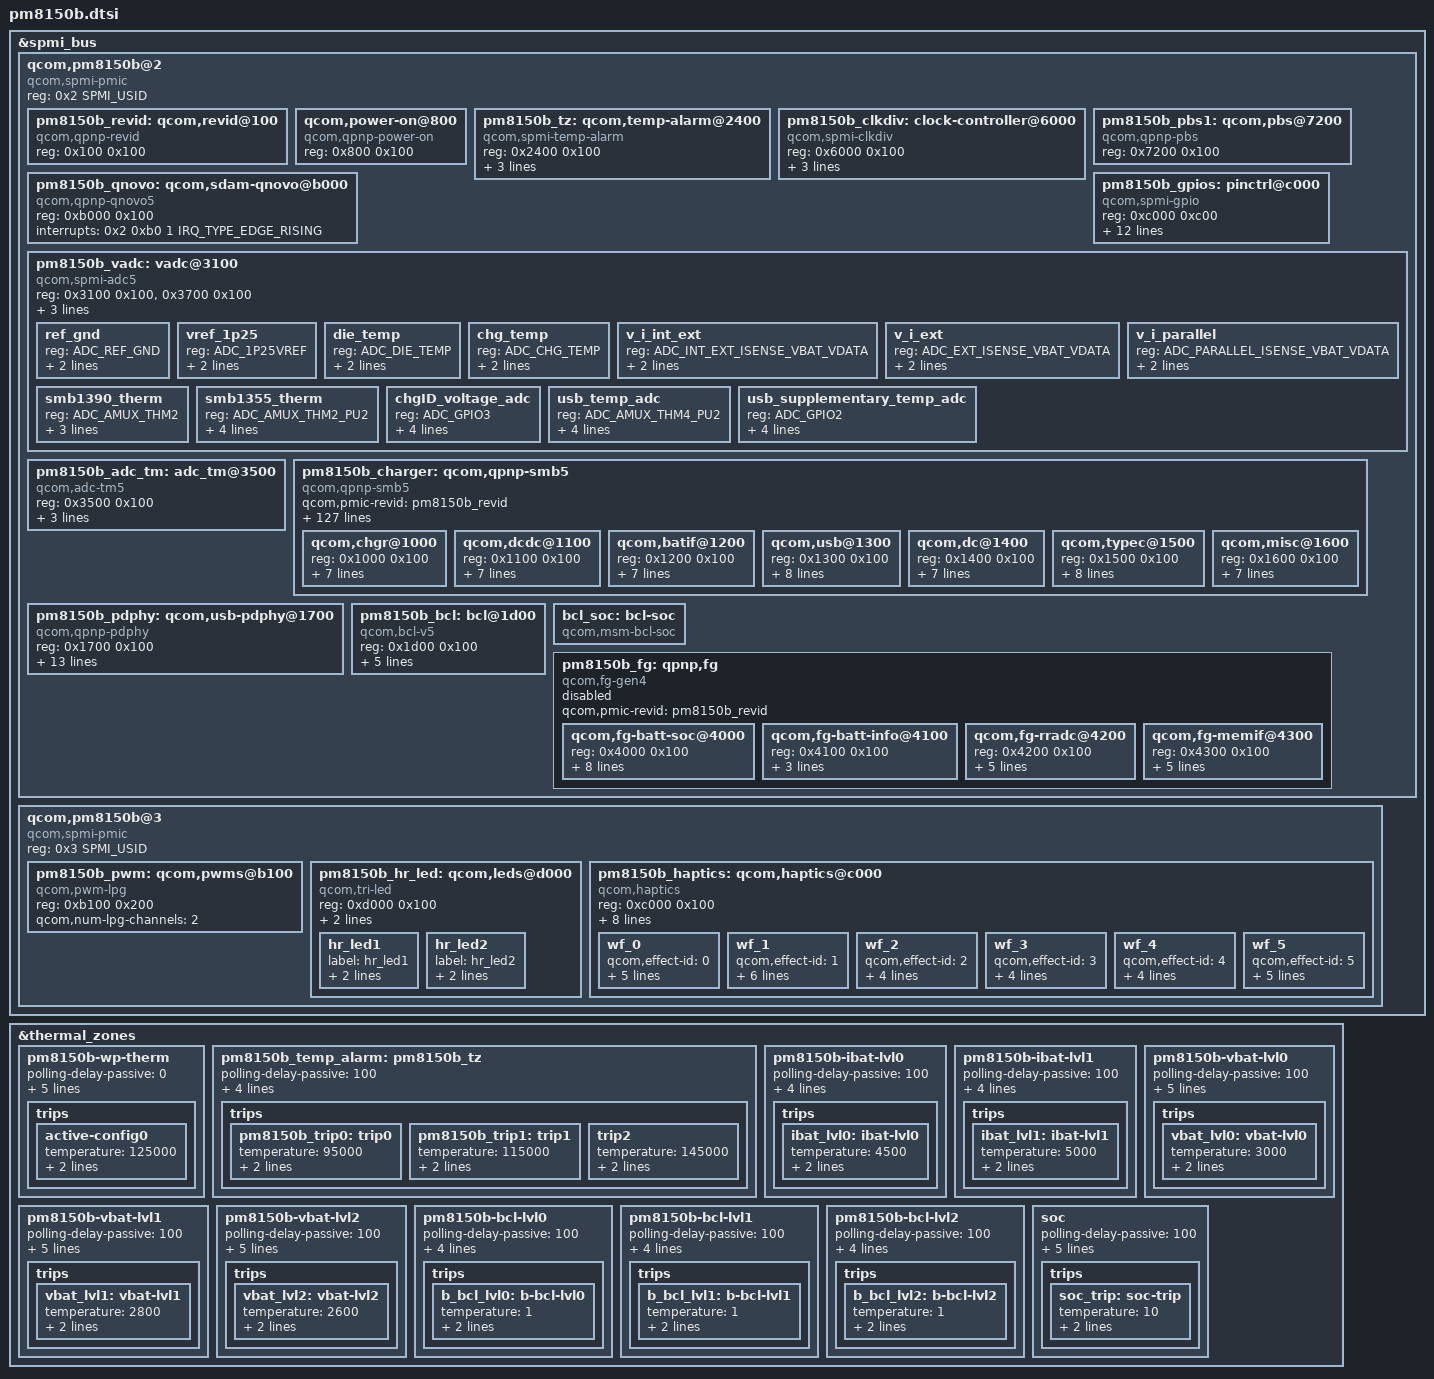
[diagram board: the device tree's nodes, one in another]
/*
 * Copyright (c) 2017-2019, The Linux Foundation. All rights reserved.
 *
 * This program is free software; you can redistribute it and/or modify
 * it under the terms of the GNU General Public License version 2 and
 * only version 2 as published by the Free Software Foundation.
 *
 * This program is distributed in the hope that it will be useful,
 * but WITHOUT ANY WARRANTY; without even the implied warranty of
 * MERCHANTABILITY or FITNESS FOR A PARTICULAR PURPOSE.  See the
 * GNU General Public License for more details.
 */

#include <dt-bindings/spmi/spmi.h>
#include <dt-bindings/interrupt-controller/irq.h>
#include <dt-bindings/iio/qcom,spmi-vadc.h>

&spmi_bus {
	#address-cells = <2>;
	#size-cells = <0>;

	qcom,pm8150b@2 {
		compatible = "qcom,spmi-pmic";
		reg = <0x2 SPMI_USID>;
		#address-cells = <2>;
		#size-cells = <0>;

		pm8150b_revid: qcom,revid@100 {
			compatible = "qcom,qpnp-revid";
			reg = <0x100 0x100>;
		};

		qcom,power-on@800 {
			compatible = "qcom,qpnp-power-on";
			reg = <0x800 0x100>;
		};

		pm8150b_tz: qcom,temp-alarm@2400 {
			compatible = "qcom,spmi-temp-alarm";
			reg = <0x2400 0x100>;
			interrupts = <0x2 0x24 0x0 IRQ_TYPE_EDGE_RISING>;
			io-channels = <&pm8150b_vadc ADC_DIE_TEMP>;
			io-channel-names = "thermal";
			#thermal-sensor-cells = <0>;
			qcom,temperature-threshold-set = <1>;
		};

		pm8150b_clkdiv: clock-controller@6000 {
			compatible = "qcom,spmi-clkdiv";
			reg = <0x6000 0x100>;
			#clock-cells = <1>;
			qcom,num-clkdivs = <1>;
			clock-output-names = "pm8150b_div_clk1";
			clocks = <&clock_rpmh RPMH_CXO_CLK>;
			clock-names = "xo";
		};

		pm8150b_pbs1: qcom,pbs@7200 {
			compatible = "qcom,qpnp-pbs";
			reg = <0x7200 0x100>;
		};

		pm8150b_qnovo: qcom,sdam-qnovo@b000 {
			compatible = "qcom,qpnp-qnovo5";
			reg = <0xb000 0x100>;
			interrupts = <0x2 0xb0 1 IRQ_TYPE_EDGE_RISING>;
			interrupt-names = "ptrain-done";
		};

		pm8150b_gpios: pinctrl@c000 {
			compatible = "qcom,spmi-gpio";
			reg = <0xc000 0xc00>;
			interrupts = <0x2 0xc0 0 IRQ_TYPE_NONE>,
					<0x2 0xc1 0 IRQ_TYPE_NONE>,
					<0x2 0xc4 0 IRQ_TYPE_NONE>,
					<0x2 0xc5 0 IRQ_TYPE_NONE>,
					//#ifdef VENDOR_EDIT
					<0x2 0xc6 0 IRQ_TYPE_NONE>,
					//#endif
					<0x2 0xc7 0 IRQ_TYPE_NONE>,
					<0x2 0xc8 0 IRQ_TYPE_NONE>,
					<0x2 0xc9 0 IRQ_TYPE_NONE>,
					<0x2 0xca 0 IRQ_TYPE_NONE>,
					<0x2 0xcb 0 IRQ_TYPE_NONE>;
			interrupt-names = "pm8150b_gpio1", "pm8150b_gpio2",
					"pm8150b_gpio5", "pm8150b_gpio6",
					//#ifdef VENDOR_EDIT
					"pm8150b_gpio7",
					//#endif
					"pm8150b_gpio8", "pm8150b_gpio9",
					"pm8150b_gpio10", "pm8150b_gpio11",
					"pm8150b_gpio12";
			gpio-controller;
			#gpio-cells = <2>;
			//#ifdef VENDOR_EDIT
			qcom,gpios-disallowed = <3 4>;
			//#else
			//qcom,gpios-disallowed = <3 4 7>;
			//#endif
		};

		pm8150b_vadc: vadc@3100 {
			compatible = "qcom,spmi-adc5";
			reg = <0x3100 0x100>, <0x3700 0x100>;
			reg-names = "adc5-usr-base", "adc5-cal-base";
			#address-cells = <1>;
			#size-cells = <0>;
			interrupts = <0x2 0x31 0x0 IRQ_TYPE_EDGE_RISING>;
			interrupt-names = "eoc-int-en-set";
			qcom,adc-vdd-reference = <1875>;
			#io-channel-cells = <1>;
			io-channel-ranges;

			/* Channel node */
			ref_gnd {
				reg = <ADC_REF_GND>;
				label = "ref_gnd";
				qcom,pre-scaling = <1 1>;
			};

			vref_1p25 {
				reg = <ADC_1P25VREF>;
				label = "vref_1p25";
				qcom,pre-scaling = <1 1>;
			};

			die_temp {
				reg = <ADC_DIE_TEMP>;
				label = "die_temp";
				qcom,pre-scaling = <1 1>;
			};

			chg_temp {
				reg = <ADC_CHG_TEMP>;
				label = "chg_temp";
				qcom,pre-scaling = <1 1>;
			};

			v_i_int_ext {
				reg = <ADC_INT_EXT_ISENSE_VBAT_VDATA>;
				label = "v_i_int_vbat_vdata";
				qcom,pre-scaling = <1 1>;
			};

			v_i_ext {
				reg = <ADC_EXT_ISENSE_VBAT_VDATA>;
				label = "v_i_int_ext_vbat_vdata";
				qcom,pre-scaling = <1 1>;
			};

			v_i_parallel {
				reg = <ADC_PARALLEL_ISENSE_VBAT_VDATA>;
				label = "v_i_parallel_vbat_vdata";
				qcom,pre-scaling = <1 1>;
			};

			smb1390_therm {
				reg = <ADC_AMUX_THM2>;
				label = "smb1390_therm";
				qcom,hw-settle-time = <200>;
				qcom,pre-scaling = <1 1>;
			};

			smb1355_therm {
				reg = <ADC_AMUX_THM2_PU2>;
				label = "smb1355_therm";
				qcom,ratiometric;
				qcom,hw-settle-time = <200>;
				qcom,pre-scaling = <1 1>;
			};
			chgID_voltage_adc {
				reg = <ADC_GPIO3>;
				label = "chgID_voltage_adc";
				qcom,pre-scaling = <1 1>;
				qcom,ratiometric;
				qcom,hw-settle-time = <200>;
			};
			usb_temp_adc {
				reg = <ADC_AMUX_THM4_PU2>;
				label = "usb_temp_adc";
				qcom,pre-scaling = <1 1>;
				qcom,ratiometric;
				qcom,hw-settle-time = <200>;
			};
			usb_supplementary_temp_adc {
				reg = <ADC_GPIO2>;
				label = "usb_supplementary_temp_adc";
				qcom,pre-scaling = <1 1>;
				qcom,ratiometric;
				qcom,hw-settle-time = <200>;
			};
			// #endif
		};

		pm8150b_adc_tm: adc_tm@3500 {
			compatible = "qcom,adc-tm5";
			reg = <0x3500 0x100>;
			interrupts = <0x2 0x35 0x0 IRQ_TYPE_EDGE_RISING>;
			interrupt-names = "thr-int-en";
			#address-cells = <1>;
			#size-cells = <0>;
			#thermal-sensor-cells = <1>;
			io-channels = <&pm8150b_vadc ADC_AMUX_THM1_PU2>;
			qcom,pmic-revid = <&pm8150b_revid>;
		};

		pm8150b_charger: qcom,qpnp-smb5 {
			compatible = "qcom,qpnp-smb5";
			#address-cells = <1>;
			#size-cells = <1>;
			#cooling-cells = <2>;

			qcom,pmic-revid = <&pm8150b_revid>;

			qcom,thermal-mitigation
					= <3000000 1500000 1000000 500000>;

			qcom,charger-temp-max = <800>;
			qcom,smb-temp-max = <800>;
			//for smb5:
			qcom,usb-icl-ua = <2000000>;
			qcom,fcc-max-ua = <2000000>;
			//qcom,fv-max-uv = <4373000>;
			qcom,hvdcp-disable;
			//io-channels = <&pm8150b_vadc ADC_GPIO3>;
			//io-channel-names = "chgID_voltage_adc";
			//qcom,otg-cl-ua = <2000000>;
			qcom,float-option = <1>;
			qcom,oplus-pps-usbpd-detection = <&pm8150b_pdphy>;

			//for oplus chg framework:
			qcom,input_current_charger_ma = <2000>;
			qcom,input_current_usb_ma = <500>;
			qcom,input_current_cdp_ma = <1500>;
			qcom,input_current_led_ma = <1200>;
			qcom,input_current_led_ma_high = <1200>;
			qcom,input_current_led_ma_warm = <1500>;
			qcom,input_current_led_ma_normal = <2000>;

			qcom,input_current_camera_ma = <1200>;
			//qcom,input_current_led_ma_overtemp = <900>;
			qcom,overtemp_bat_decidegc = <350>;
			qcom,iterm_disabled = <0>;
			qcom,iterm_ma = <215>;
			qcom,recharge-mv = <100>;
			qcom,batt_capacity_mah = <4065>;/*typical capacity*/
			//qcom,batt_capacity_mah = <3950>; /*rated capacity*/

			qcom,removed_bat_decidegc = <190>;  /*<-19C*/

			qcom,cold_bat_decidegc = <20>;  /*-2C~0C*/
			qcom,temp_cold_vfloat_mv = <3980>;
			qcom,temp_cold_fastchg_current_ma = <314>;

			qcom,little_cold_bat_decidegc = <0>;	/*0C~5C*/
			qcom,temp_little_cold_vfloat_mv = <4435>;
			qcom,temp_little_cold_fastchg_current_ma_high = <1850>;
			qcom,temp_little_cold_fastchg_current_ma_low = <1100>;
			qcom,temp_little_cold_fastchg_current_ma = <1076>;

			qcom,cool_bat_decidegc = <50>;	/*5C~12C*/
			qcom,temp_cool_vfloat_mv = <4435>;
			qcom,temp_cool_fastchg_current_ma_high = <2100>;
			qcom,temp_cool_fastchg_current_ma_low = <1850>;

			qcom,little_cool_bat_decidegc = <120>;	/*12C~16C*/
			qcom,temp_little_cool_vfloat_mv = <4435>;
			qcom,temp_little_cool_fastchg_current_ma = <2100>;

			qcom,normal_bat_decidegc = <160>;	/*16C~45C*/
			qcom,temp_normal_fastchg_current_ma = <2100>;
			qcom,temp_normal_vfloat_mv = <4435>;

			qcom,warm_bat_decidegc = <450>;		/*45C~53C*/ /*8pin Bat Vooc project need add 3 degree C*/
			qcom,temp_warm_vfloat_mv = <4130>;
			qcom,temp_warm_fastchg_current_ma = <1100>;

			qcom,hot_bat_decidegc = <530>;

			qcom,non_standard_vfloat_mv = <3980>;
			qcom,non_standard_fastchg_current_ma = <512>;

			qcom,short_c_bat_cv_mv = <4330>;
			qcom,short_c_bat_vfloat_mv = <3800>;
			qcom,short_c_bat_fastchg_current_ma = <512>;

			qcom,cold_vfloat_sw_limit = <3930>;
			qcom,little_cold_vfloat_sw_limit = <4385>;
			qcom,cool_vfloat_sw_limit = <4385>;
			qcom,little_cool_vfloat_sw_limit = <4385>;
			qcom,normal_vfloat_sw_limit = <4385>;
			qcom,warm_vfloat_sw_limit = <4080>;
			qcom,non_standard_vfloat_sw_limit = <3930>;
			qcom,short_c_bat_vfloat_sw_limit = <3750>;

			qcom,max_chg_time_sec = <36000>;
			qcom,charger_hv_thr = <5700>;
			qcom,charger_recv_thr = <5500>;
			qcom,charger_lv_thr = <3400>;
			qcom,vbatt_full_thr = <4400>;
			qcom,vbatt_hv_thr = <4500>;
			qcom,vfloat_step_mv = <8>;
			qcom,non_standard_vfloat_over_sw_limit = <3990>;
			qcom,cold_vfloat_over_sw_limit = <3990>;
			qcom,little_cold_vfloat_over_sw_limit = <4445>;
			qcom,cool_vfloat_over_sw_limit = <4445>;
			qcom,little_cool_vfloat_over_sw_limit = <4445>;
			qcom,normal_vfloat_over_sw_limit = <4445>;
			qcom,warm_vfloat_over_sw_limit = <4140>;

			qcom,vbatt_power_off = <3300>;
			qcom,vbatt_soc_1 = <3410>;
			qcom,vooc_project = <1>;
			qcom,vbatt_num = <1>;
			qcom,ffc_support;

			qcom,normal_vterm_hw_inc = <18>;
			qcom,non_normal_vterm_hw_inc = <18>;

			qcom,ff1_normal_fastchg_ma = <1060>;
			qcom,ffc2_normal_fastchg_ma = <820>;/*12C~35c*/
			qcom,ffc2_temp_warm_decidegc = <350>;
			qcom,ffc2_warm_fastchg_ma = <870>;/*35C~40c*/
			qcom,ffc2_temp_high_decidegc = <400>;
			qcom,ffc2_temp_low_decidegc = <120>;
			qcom,ffc2_exit_step_ma = <170>;

			qcom,ffc_normal_vfloat_sw_limit = <4480>;
			qcom,ffc_temp_normal_vfloat_mv = <4550>;
			qcom,ffc_normal_vfloat_over_sw_limit = <4550>;

			qcom,default_iterm_ma = <215>;
			qcom,default_temp_normal_fastchg_current_ma = <2000>;
			qcom,default_normal_vfloat_sw_limit = <4385>;
			qcom,default_temp_normal_vfloat_mv = <4435>;
			qcom,default_normal_vfloat_over_sw_limit = <4445>;

			qcom,default_temp_little_cool_fastchg_current_ma = <2000>;
			qcom,default_little_cool_vfloat_sw_limit = <4385>;
			qcom,default_temp_little_cool_vfloat_mv = <4435>;
			qcom,default_little_cool_vfloat_over_sw_limit = <4445>;

			//qcom,offset_temp = <30>;
			//for control:
			//qcom,suspend_after_full;
			qcom,check_batt_full_by_sw;
			qcom,external_gauge;
			qcom,chg_ctrl_by_lcd;
			qcom,chg_ctrl_by_camera;
			qcom,sw_vfloat_over_protect_enable;

			qcom,chargerid_switch-gpio = <&tlmm 94 0x00>;
			qcom,ship-gpio = <&tlmm 21 0x00>;
			qcom,ccdetect-gpio = <&tlmm 91 0x00>;
			//qcom,shortc-gpio = <&tlmm 43 0x00>;
			qcom,dischg-gpio = <&pm8150_gpios 9 0x00>;
			qcom,shipmode-id-gpio = <&tlmm 25 0x00>;

			pinctrl-names = "default",
					"chargerid_switch_active", "chargerid_switch_sleep", "chargerid_switch_default",
					"ship_active", "ship_sleep",
					"ccdetect_active", "ccdetect_sleep",
					"dischg_enable", "dischg_disable",
					"chg_qupv3_se12_2uart_default", "chg_qupv3_se12_2uart_sleep",
					"gpio1_adc_default",
					"shipmode_id_active";

			pinctrl-0 = <&gpio7_adc_default>;
			pinctrl-1 = <&chargerid_switch_active>;
			pinctrl-2 = <&chargerid_switch_sleep>;
			pinctrl-3 = <&chargerid_switch_default>;
			pinctrl-4 = <&ship_active>;
			pinctrl-5 = <&ship_sleep>;
			pinctrl-6 = <&ccdetect_active>;
			pinctrl-7 = <&ccdetect_sleep>;
			pinctrl-8 = <&dischg_enable>;
			pinctrl-9 = <&dischg_disable>;
			pinctrl-10 = <&chg_qupv3_se12_2uart_default>;
			pinctrl-11 = <&chg_qupv3_se12_2uart_sleep>;
			pinctrl-12 = <&gpio1_adc_default>;
			pinctrl-13 = <&shipmode_id_active>;
			//#endif //VENDOR_EDIT
			qcom,chgr@1000 {
				reg = <0x1000 0x100>;
				interrupts =
					<0x2 0x10 0x0 IRQ_TYPE_EDGE_RISING>,
					<0x2 0x10 0x1 IRQ_TYPE_EDGE_RISING>,
					<0x2 0x10 0x2 IRQ_TYPE_EDGE_RISING>,
					<0x2 0x10 0x3 IRQ_TYPE_EDGE_RISING>,
					<0x2 0x10 0x4 IRQ_TYPE_EDGE_RISING>,
					<0x2 0x10 0x6 IRQ_TYPE_EDGE_BOTH>,
					<0x2 0x10 0x7 IRQ_TYPE_EDGE_BOTH>;

				interrupt-names = "chgr-error",
						  "chg-state-change",
						  "step-chg-state-change",
						  "step-chg-soc-update-fail",
						  "step-chg-soc-update-req",
						  "vph-alarm",
						  "vph-drop-prechg";
			};

			qcom,dcdc@1100 {
				reg = <0x1100 0x100>;
				interrupts =
					<0x2 0x11 0x0 IRQ_TYPE_EDGE_BOTH>,
					<0x2 0x11 0x1 IRQ_TYPE_EDGE_BOTH>,
					<0x2 0x11 0x2 IRQ_TYPE_EDGE_BOTH>,
					<0x2 0x11 0x4 IRQ_TYPE_EDGE_BOTH>,
					<0x2 0x11 0x5 IRQ_TYPE_EDGE_BOTH>,
					<0x2 0x11 0x6 IRQ_TYPE_EDGE_BOTH>,
					<0x2 0x11 0x7 IRQ_TYPE_EDGE_BOTH>;

				interrupt-names = "otg-fail",
						  "otg-oc-disable-sw",
						  "otg-oc-hiccup",
						  "high-duty-cycle",
						  "input-current-limiting",
						  "concurrent-mode-disable",
						  "switcher-power-ok";
			};

			qcom,batif@1200 {
				reg = <0x1200 0x100>;
				interrupts =
					<0x2 0x12 0x0 IRQ_TYPE_EDGE_RISING>,
					<0x2 0x12 0x2 IRQ_TYPE_EDGE_BOTH>,
					<0x2 0x12 0x3 IRQ_TYPE_EDGE_BOTH>,
					<0x2 0x12 0x4 IRQ_TYPE_EDGE_BOTH>,
					<0x2 0x12 0x5 IRQ_TYPE_EDGE_BOTH>,
					<0x2 0x12 0x6 IRQ_TYPE_EDGE_BOTH>,
					<0x2 0x12 0x7 IRQ_TYPE_EDGE_BOTH>;

				interrupt-names = "bat-temp",
						  "bat-ov",
						  "bat-low",
						  "bat-therm-or-id-missing",
						  "bat-terminal-missing",
						  "buck-oc",
						  "vph-ov";
			};

			qcom,usb@1300 {
				reg = <0x1300 0x100>;
				interrupts =
					<0x2 0x13 0x0 IRQ_TYPE_EDGE_BOTH>,
					<0x2 0x13 0x1 IRQ_TYPE_EDGE_BOTH>,
					<0x2 0x13 0x2 IRQ_TYPE_EDGE_BOTH>,
					<0x2 0x13 0x3 IRQ_TYPE_EDGE_BOTH>,
					<0x2 0x13 0x4 IRQ_TYPE_EDGE_BOTH>,
					<0x2 0x13 0x5 IRQ_TYPE_EDGE_BOTH>,
					<0x2 0x13 0x6 IRQ_TYPE_EDGE_RISING>,
					<0x2 0x13 0x7 IRQ_TYPE_EDGE_RISING>;

				interrupt-names = "usbin-collapse",
						  "usbin-vashdn",
						  "usbin-uv",
						  "usbin-ov",
						  "usbin-plugin",
						  "usbin-revi-change",
						  "usbin-src-change",
						  "usbin-icl-change";
			};

			qcom,dc@1400 {
				reg = <0x1400 0x100>;
				interrupts =
					<0x2 0x14 0x1 IRQ_TYPE_EDGE_BOTH>,
					<0x2 0x14 0x2 IRQ_TYPE_EDGE_BOTH>,
					<0x2 0x14 0x3 IRQ_TYPE_EDGE_BOTH>,
					<0x2 0x14 0x4 IRQ_TYPE_EDGE_BOTH>,
					<0x2 0x14 0x5 IRQ_TYPE_EDGE_BOTH>,
					<0x2 0x14 0x6 IRQ_TYPE_EDGE_BOTH>,
					<0x2 0x14 0x7 IRQ_TYPE_EDGE_BOTH>;

				interrupt-names = "dcin-vashdn",
						  "dcin-uv",
						  "dcin-ov",
						  "dcin-plugin",
						  "dcin-revi",
						  "dcin-pon",
						  "dcin-en";
			};

			qcom,typec@1500 {
				reg = <0x1500 0x100>;
				interrupts =
					<0x2 0x15 0x0 IRQ_TYPE_EDGE_RISING>,
					<0x2 0x15 0x1 IRQ_TYPE_EDGE_BOTH>,
					<0x2 0x15 0x2 IRQ_TYPE_EDGE_RISING>,
					<0x2 0x15 0x3 IRQ_TYPE_EDGE_BOTH>,
					<0x2 0x15 0x4 IRQ_TYPE_EDGE_RISING>,
					<0x2 0x15 0x5 IRQ_TYPE_EDGE_RISING>,
					<0x2 0x15 0x6 IRQ_TYPE_EDGE_BOTH>,
					<0x2 0x15 0x7 IRQ_TYPE_EDGE_RISING>;

				interrupt-names = "typec-or-rid-detect-change",
						  "typec-vpd-detect",
						  "typec-cc-state-change",
						  "typec-vconn-oc",
						  "typec-vbus-change",
						  "typec-attach-detach",
						  "typec-legacy-cable-detect",
						  "typec-try-snk-src-detect";
			};

			qcom,misc@1600 {
				reg = <0x1600 0x100>;
				interrupts =
					<0x2 0x16 0x0 IRQ_TYPE_EDGE_RISING>,
					<0x2 0x16 0x1 IRQ_TYPE_EDGE_RISING>,
					<0x2 0x16 0x2 IRQ_TYPE_EDGE_BOTH>,
					<0x2 0x16 0x3 IRQ_TYPE_EDGE_BOTH>,
					<0x2 0x16 0x4 IRQ_TYPE_EDGE_BOTH>,
					<0x2 0x16 0x6 IRQ_TYPE_EDGE_BOTH>,
					<0x2 0x16 0x7 IRQ_TYPE_EDGE_BOTH>;

				interrupt-names = "wdog-snarl",
						  "wdog-bark",
						  "aicl-fail",
						  "aicl-done",
						  "smb-en",
						  "temp-change",
						  "temp-change-smb";
			};
		};

		pm8150b_pdphy: qcom,usb-pdphy@1700 {
			compatible = "qcom,qpnp-pdphy";
			reg = <0x1700 0x100>;
			vdd-pdphy-supply = <&pm8150_l2>;
			vbus-supply = <&smb5_vbus>;
			vconn-supply = <&smb5_vconn>;
			interrupts = <0x2 0x17 0x0 IRQ_TYPE_EDGE_RISING>,
				     <0x2 0x17 0x1 IRQ_TYPE_EDGE_RISING>,
				     <0x2 0x17 0x2 IRQ_TYPE_EDGE_RISING>,
				     <0x2 0x17 0x3 IRQ_TYPE_EDGE_RISING>,
				     <0x2 0x17 0x4 IRQ_TYPE_EDGE_RISING>,
				     <0x2 0x17 0x5 IRQ_TYPE_EDGE_RISING>,
				     <0x2 0x17 0x6 IRQ_TYPE_EDGE_RISING>,
				     <0x2 0x17 0x7 IRQ_TYPE_EDGE_RISING>;

			interrupt-names = "sig-tx",
					  "sig-rx",
					  "msg-tx",
					  "msg-rx",
					  "msg-tx-failed",
					  "msg-tx-discarded",
					  "msg-rx-discarded",
					  "fr-swap";

			qcom,default-sink-caps = <5000 3000>, /* 5V @ 3A */
						 <9000 3000>, /* 9V @ 3A */
						 <12000 2250>; /* 12V @ 2.25A */
		};

		pm8150b_bcl: bcl@1d00 {
			compatible = "qcom,bcl-v5";
			reg = <0x1d00 0x100>;
			interrupts = <0x2 0x1d 0x0 IRQ_TYPE_NONE>,
					<0x2 0x1d 0x1 IRQ_TYPE_NONE>,
					<0x2 0x1d 0x0 IRQ_TYPE_NONE>,
					<0x2 0x1d 0x1 IRQ_TYPE_NONE>,
					<0x2 0x1d 0x2 IRQ_TYPE_NONE>;
			interrupt-names = "bcl-ibat-lvl0",
						"bcl-ibat-lvl1",
						"bcl-vbat-lvl0",
						"bcl-vbat-lvl1",
						"bcl-vbat-lvl2";
			#thermal-sensor-cells = <1>;
		};

		bcl_soc:bcl-soc {
			compatible = "qcom,msm-bcl-soc";
			#thermal-sensor-cells = <0>;
		};

		pm8150b_fg: qpnp,fg {
			compatible = "qcom,fg-gen4";
			#address-cells = <1>;
			#size-cells = <1>;
			qcom,pmic-revid = <&pm8150b_revid>;
			//#ifndef VENDOR_EDIT
			//status = "okay";
			//#else
			status = "disable";
			//#endif

			qcom,fg-batt-soc@4000 {
				status = "okay";
				reg = <0x4000 0x100>;
				interrupts = <0x2 0x40 0x0 IRQ_TYPE_EDGE_BOTH>,
					     <0x2 0x40 0x1 IRQ_TYPE_EDGE_BOTH>,
					     <0x2 0x40 0x2
							IRQ_TYPE_EDGE_RISING>,
					     <0x2 0x40 0x3
							IRQ_TYPE_EDGE_RISING>,
					     <0x2 0x40 0x4 IRQ_TYPE_EDGE_BOTH>,
					     <0x2 0x40 0x5
							IRQ_TYPE_EDGE_RISING>,
					     <0x2 0x40 0x6 IRQ_TYPE_EDGE_BOTH>,
					     <0x2 0x40 0x7 IRQ_TYPE_EDGE_BOTH>;
				interrupt-names = "soc-update",
						  "soc-ready",
						  "bsoc-delta",
						  "msoc-delta",
						  "msoc-low",
						  "msoc-empty",
						  "msoc-high",
						  "msoc-full";
			};

			qcom,fg-batt-info@4100 {
				status = "okay";
				reg = <0x4100 0x100>;
				interrupts = <0x2 0x41 0x0 IRQ_TYPE_EDGE_BOTH>,
					     <0x2 0x41 0x1 IRQ_TYPE_EDGE_BOTH>,
					     <0x2 0x41 0x3
							IRQ_TYPE_EDGE_RISING>;
				interrupt-names = "vbatt-low",
						  "vbatt-pred-delta",
						  "esr-delta";
			};

			qcom,fg-rradc@4200 {
				status = "okay";
				reg = <0x4200 0x100>;
				interrupts = <0x2 0x42 0x0 IRQ_TYPE_EDGE_BOTH>,
					     <0x2 0x42 0x1 IRQ_TYPE_EDGE_BOTH>,
					     <0x2 0x42 0x2 IRQ_TYPE_EDGE_BOTH>,
					     <0x2 0x42 0x3 IRQ_TYPE_EDGE_BOTH>,
					     <0x2 0x42 0x4 IRQ_TYPE_EDGE_BOTH>;
				interrupt-names = "batt-missing",
						  "batt-id",
						  "batt-temp-delta",
						  "batt-temp-hot",
						  "batt-temp-cold";
			};

			qcom,fg-memif@4300 {
				status = "okay";
				reg = <0x4300 0x100>;
				interrupts = <0x2 0x43 0x0 IRQ_TYPE_EDGE_BOTH>,
					     <0x2 0x43 0x1 IRQ_TYPE_EDGE_BOTH>,
					     <0x2 0x43 0x2 IRQ_TYPE_EDGE_BOTH>,
					     <0x2 0x43 0x3
							IRQ_TYPE_EDGE_RISING>,
					     <0x2 0x43 0x4
							IRQ_TYPE_EDGE_FALLING>;
				interrupt-names = "ima-rdy",
						  "ima-xcp",
						  "dma-xcp",
						  "dma-grant",
						  "mem-attn";
			};
		};
	};

	qcom,pm8150b@3 {
		compatible ="qcom,spmi-pmic";
		reg = <0x3 SPMI_USID>;
		#address-cells = <2>;
		#size-cells = <0>;

		pm8150b_pwm: qcom,pwms@b100 {
			compatible = "qcom,pwm-lpg";
			reg = <0xb100 0x200>;
			reg-names = "lpg-base";
			#pwm-cells = <2>;
			qcom,num-lpg-channels = <2>;
		};

		pm8150b_hr_led: qcom,leds@d000 {
			compatible = "qcom,tri-led";
			reg = <0xd000 0x100>;
			nvmem-names = "pbs_sdam";
			nvmem = <&pm8150_sdam_2>;
			hr_led1 {
				label = "hr_led1";
				pwms = <&pm8150b_pwm 0 1000000>;
				led-sources = <0>;
			};
			hr_led2 {
				label = "hr_led2";
				pwms = <&pm8150b_pwm 1 1000000>;
				led-sources = <1>;
			};
		};

		pm8150b_haptics: qcom,haptics@c000 {
			compatible = "qcom,haptics";
			reg = <0xc000 0x100>;
			interrupts = <0x3 0xc0 0x0 IRQ_TYPE_EDGE_BOTH>,
				     <0x3 0xc0 0x1 IRQ_TYPE_EDGE_BOTH>;
			interrupt-names = "hap-sc-irq", "hap-play-irq";
			qcom,actuator-type = "lra";
			qcom,vmax-mv = <3400>;
			qcom,play-rate-us = <6667>;
			qcom,lra-resonance-sig-shape = "sine";
			qcom,lra-auto-resonance-mode = "qwd";
			qcom,lra-allow-variable-play-rate;

			wf_0 {
				/* CLICK */
				qcom,effect-id = <0>;
				qcom,wf-vmax-mv = <3600>;
				qcom,wf-pattern = [3e 3e 3e];
				qcom,wf-play-rate-us = <6667>;
				qcom,wf-brake-pattern = [01 00 00 00];
				qcom,lra-auto-resonance-disable;
			};
			wf_1 {
				/* DOUBLE CLICK */
				qcom,effect-id = <1>;
				qcom,wf-vmax-mv = <3600>;
				qcom,wf-pattern = [7e 7e 02 02 02 02 02 02];
				qcom,wf-play-rate-us = <7143>;
				qcom,wf-repeat-count = <2>;
				qcom,wf-s-repeat-count = <1>;
				qcom,lra-auto-resonance-disable;
			};
			wf_2 {
				/* TICK */
				qcom,effect-id = <2>;
				qcom,wf-vmax-mv = <3600>;
				qcom,wf-pattern = [7e 7e];
				qcom,wf-play-rate-us = <4000>;
				qcom,lra-auto-resonance-disable;
			};
			wf_3 {
				/* THUD */
				qcom,effect-id = <3>;
				qcom,wf-vmax-mv = <3600>;
				qcom,wf-pattern = [7e 7e 7e];
				qcom,wf-play-rate-us = <6667>;
				qcom,lra-auto-resonance-disable;
			};
			wf_4 {
				/* POP */
				qcom,effect-id = <4>;
				qcom,wf-vmax-mv = <3600>;
				qcom,wf-pattern = [7e 7e];
				qcom,wf-play-rate-us = <5000>;
				qcom,lra-auto-resonance-disable;
			};
			wf_5 {
				/* HEAVY CLICK */
				qcom,effect-id = <5>;
				qcom,wf-vmax-mv = <3600>;
				qcom,wf-pattern = [7e 7e 7e];
				qcom,wf-play-rate-us = <6667>;
				qcom,wf-brake-pattern = [03 00 00 00];
				qcom,lra-auto-resonance-disable;
			};
		};
	};
};

&thermal_zones {
	pm8150b-wp-therm {
		polling-delay-passive = <0>;
		polling-delay = <0>;
		thermal-governor = "user_space";
		thermal-sensors = <&pm8150b_adc_tm ADC_AMUX_THM2_PU2>;
		wake-capable-sensor;
		trips {
			active-config0 {
				temperature = <125000>;
				hysteresis = <1000>;
				type = "passive";
			};
		};
	};

	pm8150b_temp_alarm: pm8150b_tz {
		polling-delay-passive = <100>;
		polling-delay = <0>;
		thermal-governor = "step_wise";
		thermal-sensors = <&pm8150b_tz>;
		wake-capable-sensor;

		trips {
			pm8150b_trip0: trip0 {
				temperature = <95000>;
				hysteresis = <0>;
				type = "passive";
			};
			pm8150b_trip1: trip1 {
				temperature = <115000>;
				hysteresis = <0>;
				type = "passive";
			};
			trip2 {
				temperature = <145000>;
				hysteresis = <0>;
				type = "passive";
			};
		};
	};

	pm8150b-ibat-lvl0 {
		polling-delay-passive = <100>;
		polling-delay = <0>;
		thermal-governor = "step_wise";
		thermal-sensors = <&pm8150b_bcl 0>;
		wake-capable-sensor;

		trips {
			ibat_lvl0:ibat-lvl0 {
				temperature = <4500>;
				hysteresis = <200>;
				type = "passive";
			};
		};
	};

	pm8150b-ibat-lvl1 {
		polling-delay-passive = <100>;
		polling-delay = <0>;
		thermal-governor = "step_wise";
		thermal-sensors = <&pm8150b_bcl 1>;
		wake-capable-sensor;

		trips {
			ibat_lvl1:ibat-lvl1 {
				temperature = <5000>;
				hysteresis = <200>;
				type = "passive";
			};
		};
	};

	pm8150b-vbat-lvl0 {
		polling-delay-passive = <100>;
		polling-delay = <0>;
		thermal-governor = "low_limits_cap";
		thermal-sensors = <&pm8150b_bcl 2>;
		wake-capable-sensor;
		tracks-low;

		trips {
			vbat_lvl0: vbat-lvl0 {
				temperature = <3000>;
				hysteresis = <200>;
				type = "passive";
			};
		};
	};

	pm8150b-vbat-lvl1 {
		polling-delay-passive = <100>;
		polling-delay = <0>;
		thermal-governor = "low_limits_cap";
		thermal-sensors = <&pm8150b_bcl 3>;
		wake-capable-sensor;
		tracks-low;

		trips {
			vbat_lvl1:vbat-lvl1 {
				temperature = <2800>;
				hysteresis = <200>;
				type = "passive";
			};
		};
	};

	pm8150b-vbat-lvl2 {
		polling-delay-passive = <100>;
		polling-delay = <0>;
		thermal-governor = "low_limits_cap";
		thermal-sensors = <&pm8150b_bcl 4>;
		wake-capable-sensor;
		tracks-low;

		trips {
			vbat_lvl2:vbat-lvl2 {
				temperature = <2600>;
				hysteresis = <200>;
				type = "passive";
			};
		};
	};

	pm8150b-bcl-lvl0 {
		polling-delay-passive = <100>;
		polling-delay = <0>;
		thermal-governor = "step_wise";
		thermal-sensors = <&pm8150b_bcl 5>;
		wake-capable-sensor;

		trips {
			b_bcl_lvl0: b-bcl-lvl0 {
				temperature = <1>;
				hysteresis = <1>;
				type = "passive";
			};
		};
	};

	pm8150b-bcl-lvl1 {
		polling-delay-passive = <100>;
		polling-delay = <0>;
		thermal-governor = "step_wise";
		thermal-sensors = <&pm8150b_bcl 6>;
		wake-capable-sensor;

		trips {
			b_bcl_lvl1: b-bcl-lvl1 {
				temperature = <1>;
				hysteresis = <1>;
				type = "passive";
			};
		};
	};

	pm8150b-bcl-lvl2 {
		polling-delay-passive = <100>;
		polling-delay = <0>;
		thermal-governor = "step_wise";
		thermal-sensors = <&pm8150b_bcl 7>;
		wake-capable-sensor;

		trips {
			b_bcl_lvl2: b-bcl-lvl2 {
				temperature = <1>;
				hysteresis = <1>;
				type = "passive";
			};
		};
	};

	soc {
		polling-delay-passive = <100>;
		polling-delay = <0>;
		thermal-governor = "low_limits_cap";
		thermal-sensors = <&bcl_soc>;
		wake-capable-sensor;
		tracks-low;

		trips {
			soc_trip:soc-trip {
				temperature = <10>;
				hysteresis = <0>;
				type = "passive";
			};
		};
	};
};
